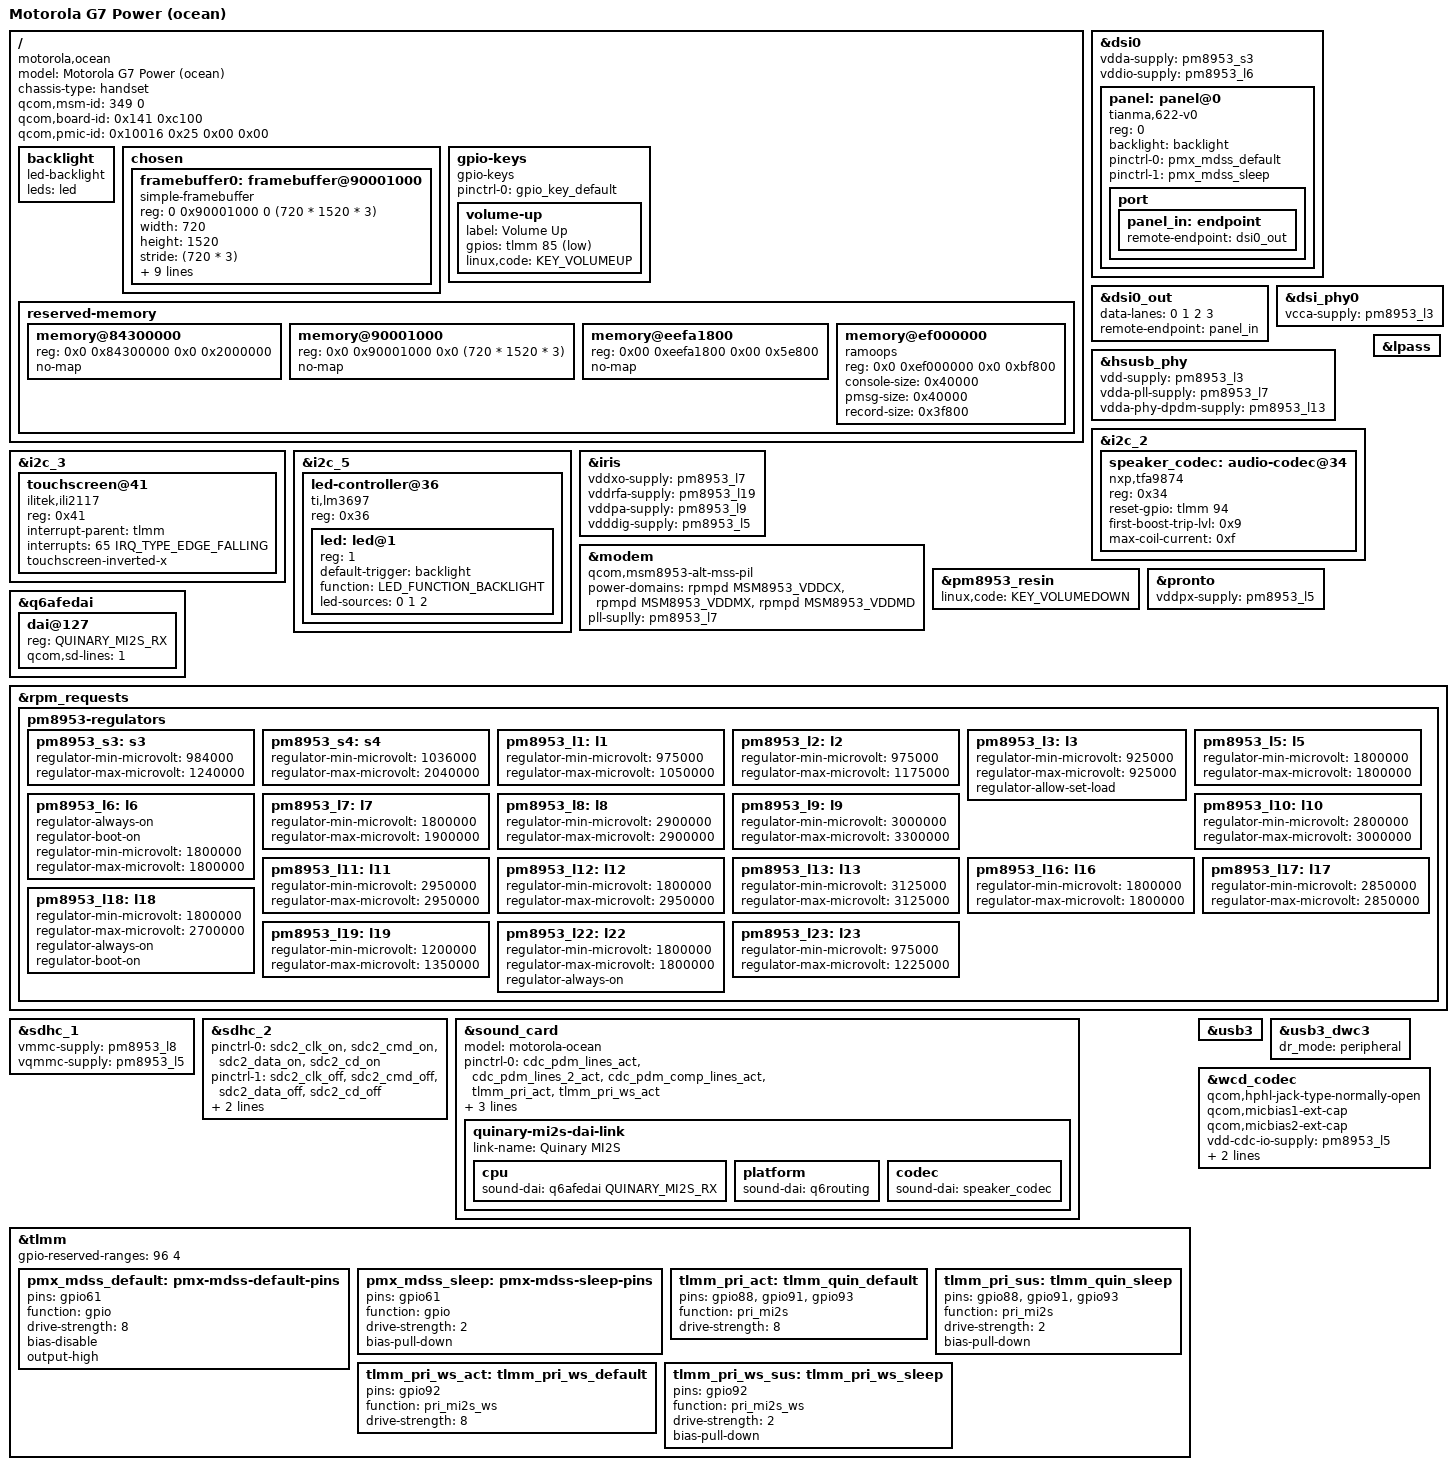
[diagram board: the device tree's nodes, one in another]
// SPDX-License-Identifier: GPL-2.0-only

/dts-v1/;

#include "msm8953.dtsi"
#include "pm8953.dtsi"
#include "sdm632.dtsi"

#include <dt-bindings/leds/common.h>

/ {
	model = "Motorola G7 Power (ocean)";
	compatible = "motorola,ocean", "qcom,sdm632";
	chassis-type = "handset";
	qcom,msm-id = <349 0>;
	qcom,board-id = <0x141 0xc100>;
	qcom,pmic-id = <0x10016 0x25 0x00 0x00>;

	backlight: backlight {
		compatible = "led-backlight";
		leds = <&led>;
	};

	chosen {
		#address-cells = <2>;
		#size-cells = <2>;
		ranges;

		framebuffer0: framebuffer@90001000 {
			compatible = "simple-framebuffer";
			reg = <0 0x90001000 0 (720 * 1520 * 3)>;

			width = <720>;
			height = <1520>;
			stride = <(720 * 3)>;
			format = "r8g8b8";

			power-domains = <&gcc MDSS_GDSC>;

			clocks = <&gcc GCC_MDSS_AHB_CLK>,
				 <&gcc GCC_MDSS_AXI_CLK>,
				 <&gcc GCC_MDSS_VSYNC_CLK>,
				 <&gcc GCC_MDSS_MDP_CLK>,
				 <&gcc GCC_MDSS_BYTE0_CLK>,
				 <&gcc GCC_MDSS_PCLK0_CLK>,
				 <&gcc GCC_MDSS_ESC0_CLK>;
		};
	};

	gpio-keys {
		compatible = "gpio-keys";

		pinctrl-names = "default";
		pinctrl-0 = <&gpio_key_default>;

		volume-up {
			label = "Volume Up";
			gpios = <&tlmm 85 GPIO_ACTIVE_LOW>;
			linux,code = <KEY_VOLUMEUP>;
		};
	};

	reserved-memory {
		/delete-node/memory@85b00000;

		memory@84300000 {
			reg = <0x0 0x84300000 0x0 0x2000000>;
			no-map;
		};

		memory@90001000 {
			reg = <0x0 0x90001000 0x0 (720 * 1520 * 3)>;
			no-map;
		};

		memory@eefa1800 {
			reg = <0x00 0xeefa1800 0x00 0x5e800>;
			no-map;
		};

		memory@ef000000 {
			compatible = "ramoops";
			reg = <0x0 0xef000000 0x0 0xbf800>;
			console-size = <0x40000>;
			pmsg-size = <0x40000>;
			record-size = <0x3f800>;
		};
	};
};

&dsi0 {
	vdda-supply = <&pm8953_s3>;
	vddio-supply = <&pm8953_l6>;

	panel: panel@0 {
		compatible = "tianma,622-v0";
		reg = <0>;

		backlight = <&backlight>;

		pinctrl-names = "default", "sleep";
		pinctrl-0 = <&pmx_mdss_default>;
		pinctrl-1 = <&pmx_mdss_sleep>;

		port {
			panel_in: endpoint {
				remote-endpoint = <&dsi0_out>;
			};
		};
	};
};

&dsi0_out {
	data-lanes = <0 1 2 3>;
	remote-endpoint = <&panel_in>;
};

&dsi_phy0 {
	vcca-supply = <&pm8953_l3>;
};

&hsusb_phy {
	status = "okay";

	vdd-supply = <&pm8953_l3>;
	vdda-pll-supply = <&pm8953_l7>;
	vdda-phy-dpdm-supply = <&pm8953_l13>;
};

&i2c_2 {
	status = "okay";

	speaker_codec: audio-codec@34 {
		compatible = "nxp,tfa9874";
		reg = <0x34>;

		reset-gpio = <&tlmm 94 GPIO_ACTIVE_HIGH>;

		first-boost-trip-lvl = <0x9>;
		max-coil-current = <0xf>;

		#sound-dai-cells = <0>;
	};
};

&i2c_3 {
	status = "okay";

	touchscreen@41 {
		compatible = "ilitek,ili2117";
		reg = <0x41>;

		interrupt-parent = <&tlmm>;
		interrupts = <65 IRQ_TYPE_EDGE_FALLING>;

		touchscreen-inverted-x;
	};
};

&i2c_5 {
	status = "okay";

	led-controller@36 {
		compatible = "ti,lm3697";
		reg = <0x36>;

		#address-cells = <1>;
		#size-cells = <0>;

		led: led@1 {
			reg = <1>;
			default-trigger = "backlight";
			function = LED_FUNCTION_BACKLIGHT;
			led-sources = <0 1 2>;
		};
	};
};

&iris {
	vddxo-supply = <&pm8953_l7>;
	vddrfa-supply = <&pm8953_l19>;
	vddpa-supply = <&pm8953_l9>;
	vdddig-supply = <&pm8953_l5>;
};

&lpass {
	status = "okay";
};

&modem {
	compatible = "qcom,msm8953-alt-mss-pil";
	status = "okay";

	power-domains = <&rpmpd MSM8953_VDDCX>, <&rpmpd MSM8953_VDDMX>, <&rpmpd MSM8953_VDDMD>;
	power-domain-names = "cx", "mx", "mss";

	pll-suplly = <&pm8953_l7>;
};

&pm8953_resin {
	status = "okay";
	linux,code = <KEY_VOLUMEDOWN>;
};

&pronto {
	status = "okay";

	vddpx-supply = <&pm8953_l5>;
};

&q6afedai {
	dai@127 {
		reg = <QUINARY_MI2S_RX>;
		qcom,sd-lines = <1>;
	};
};

&rpm_requests {
	pm8953-regulators {
		// TODO Add supplies

		pm8953_s3: s3 {
			regulator-min-microvolt = <984000>;
			regulator-max-microvolt = <1240000>;
		};

		pm8953_s4: s4 {
			regulator-min-microvolt = <1036000>;
			regulator-max-microvolt = <2040000>;
		};

		pm8953_l1: l1 {
			regulator-min-microvolt = <975000>;
			regulator-max-microvolt = <1050000>;
		};

		pm8953_l2: l2 {
			regulator-min-microvolt = <975000>;
			regulator-max-microvolt = <1175000>;
		};

		pm8953_l3: l3 {
			regulator-min-microvolt = <925000>;
			regulator-max-microvolt = <925000>;
			regulator-allow-set-load;
		};

		pm8953_l5: l5 {
			regulator-min-microvolt = <1800000>;
			regulator-max-microvolt = <1800000>;
		};

		pm8953_l6: l6 { // other ocean models use l22 instead
			regulator-always-on;
			regulator-boot-on;
			regulator-min-microvolt = <1800000>;
			regulator-max-microvolt = <1800000>;
		};

		pm8953_l7: l7 {
			regulator-min-microvolt = <1800000>;
			regulator-max-microvolt = <1900000>;
		};

		pm8953_l8: l8 {
			regulator-min-microvolt = <2900000>;
			regulator-max-microvolt = <2900000>;
		};

		pm8953_l9: l9 {
			regulator-min-microvolt = <3000000>;
			regulator-max-microvolt = <3300000>;
		};

		pm8953_l10: l10 {
			regulator-min-microvolt = <2800000>;
			regulator-max-microvolt = <3000000>;
		};

		pm8953_l11: l11 {
			regulator-min-microvolt = <2950000>;
			regulator-max-microvolt = <2950000>;
		};

		pm8953_l12: l12 {
			regulator-min-microvolt = <1800000>;
			regulator-max-microvolt = <2950000>;
		};

		pm8953_l13: l13 {
			regulator-min-microvolt = <3125000>;
			regulator-max-microvolt = <3125000>;
		};

		pm8953_l16: l16 {
			regulator-min-microvolt = <1800000>;
			regulator-max-microvolt = <1800000>;
		};

		pm8953_l17: l17 {
			regulator-min-microvolt = <2850000>;
			regulator-max-microvolt = <2850000>;
		};

		pm8953_l18: l18 {
			regulator-min-microvolt = <1800000>;
			regulator-max-microvolt = <2700000>;
			regulator-always-on;
			regulator-boot-on;
		};

		pm8953_l19: l19 {
			regulator-min-microvolt = <1200000>;
			regulator-max-microvolt = <1350000>;
		};

		pm8953_l22: l22 {
			regulator-min-microvolt = <1800000>;
			regulator-max-microvolt = <1800000>;
			regulator-always-on;
		};

		pm8953_l23: l23 {
			regulator-min-microvolt = <975000>;
			regulator-max-microvolt = <1225000>;
		};
	};
};

&sdhc_1 {
	status = "okay";

	vmmc-supply = <&pm8953_l8>;
	vqmmc-supply = <&pm8953_l5>;
};

&sdhc_2 {
	status = "okay";

	pinctrl-names = "default", "sleep";
	pinctrl-0 = <&sdc2_clk_on &sdc2_cmd_on &sdc2_data_on &sdc2_cd_on>;
	pinctrl-1 = <&sdc2_clk_off &sdc2_cmd_off &sdc2_data_off &sdc2_cd_off>;

	vmmc-supply = <&pm8953_l11>;
	vqmmc-supply = <&pm8953_l12>;
};

&sound_card {
	status = "okay";

	model = "motorola-ocean";

	pinctrl-names = "default", "sleep";
	pinctrl-0 = <&cdc_pdm_lines_act &cdc_pdm_lines_2_act &cdc_pdm_comp_lines_act &tlmm_pri_act &tlmm_pri_ws_act>;
	pinctrl-1 = <&cdc_pdm_lines_sus &cdc_pdm_lines_2_sus &cdc_pdm_comp_lines_act &tlmm_pri_sus &tlmm_pri_ws_sus>;

	quinary-mi2s-dai-link {
		link-name = "Quinary MI2S";
		cpu {
			sound-dai = <&q6afedai QUINARY_MI2S_RX>;
		};

		platform {
			sound-dai = <&q6routing>;
		};

		codec {
			sound-dai = <&speaker_codec>;
		};
	};
};

&tlmm {
	gpio-reserved-ranges = <96 4>;

	pmx_mdss_default: pmx-mdss-default-pins {
		pins = "gpio61";
		function = "gpio";
		drive-strength = <8>;
		bias-disable;
		output-high;
	};

	pmx_mdss_sleep: pmx-mdss-sleep-pins {
		pins = "gpio61";
		function = "gpio";
		drive-strength = <2>;
		bias-pull-down;
	};

	tlmm_pri_act: tlmm_quin_default {
		pins = "gpio88", "gpio91", "gpio93";
		function = "pri_mi2s";
		drive-strength = <8>;
		/* bias-disable; */
	};

	tlmm_pri_sus: tlmm_quin_sleep {
		pins = "gpio88", "gpio91", "gpio93";
		function = "pri_mi2s";
		drive-strength = <2>;
		bias-pull-down;
	};

	tlmm_pri_ws_act: tlmm_pri_ws_default {
		pins = "gpio92";
		function = "pri_mi2s_ws";
		drive-strength = <8>;
	};

	tlmm_pri_ws_sus: tlmm_pri_ws_sleep {
		pins = "gpio92";
		function = "pri_mi2s_ws";
		drive-strength = <2>;
		bias-pull-down;
	};
};

&usb3 {
	status = "okay";
};

&usb3_dwc3 {
	dr_mode = "peripheral";
};

&wcd_codec {
	status = "okay";

	qcom,hphl-jack-type-normally-open;
	qcom,micbias1-ext-cap;
	qcom,micbias2-ext-cap;

	vdd-cdc-io-supply = <&pm8953_l5>;
	vdd-cdc-tx-rx-cx-supply = <&pm8953_s4>;
	vdd-micbias-supply = <&pm8953_l13>;
};
